# STM32L053C6T6 register map
File version: 1.0
Registers are 32-bit, access not given, reset 0x0 unless marked. A register's access mark holds for its fields unless they carry their own. Offsets are from the block's base; [hi:lo] are bit positions; {n}, {i} and the like mark numbered series.

## LPUART1
Base 0x40004800
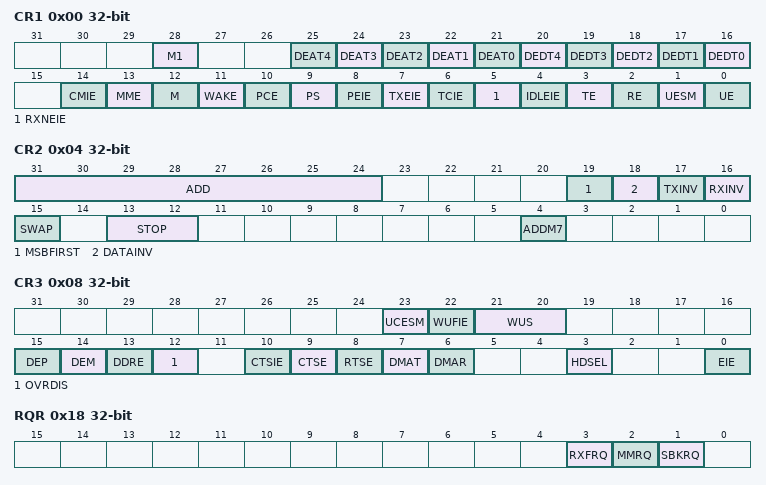
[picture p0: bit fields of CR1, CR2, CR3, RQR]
0x00 CR1
  [28] M1, [n+21] DEAT{n} (n=0..4), [n+16] DEDT{n} (n=0..4), [14] CMIE, [13] MME, [12] M, [11] WAKE, [10] PCE, [9] PS, [8] PEIE, [7] TXEIE, [6] TCIE, [5] RXNEIE, [4] IDLEIE, [3] TE, [2] RE, [1] UESM, [0] UE
0x04 CR2
  [31:24] ADD, [19] MSBFIRST, [18] DATAINV, [17] TXINV, [16] RXINV, [15] SWAP, [13:12] STOP, [4] ADDM7
0x08 CR3
  [23] UCESM, [22] WUFIE, [21:20] WUS, [15] DEP, [14] DEM, [13] DDRE, [12] OVRDIS, [10] CTSIE, [9] CTSE, [8] RTSE, [7] DMAT, [6] DMAR, [3] HDSEL, [0] EIE
0x0C BRR
  [19:0] BRR
0x18 RQR
  [3] RXFRQ, [2] MMRQ, [1] SBKRQ
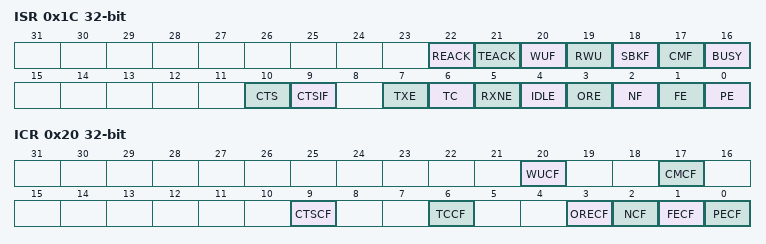
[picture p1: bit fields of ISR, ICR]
0x1C ISR
  [22] REACK, [21] TEACK, [20] WUF, [19] RWU, [18] SBKF, [17] CMF, [16] BUSY, [10] CTS, [9] CTSIF, [7] TXE, [6] TC, [5] RXNE, [4] IDLE, [3] ORE, [2] NF, [1] FE, [0] PE
0x20 ICR
  [20] WUCF, [17] CMCF, [9] CTSCF, [6] TCCF, [3] ORECF, [2] NCF, [1] FECF, [0] PECF
0x24 RDR
  [8:0] RDR
0x28 TDR
  [8:0] TDR

## I2C1
Base 0x40005400
Same registers: I2C2 0x40005800, I2C3 0x40007800
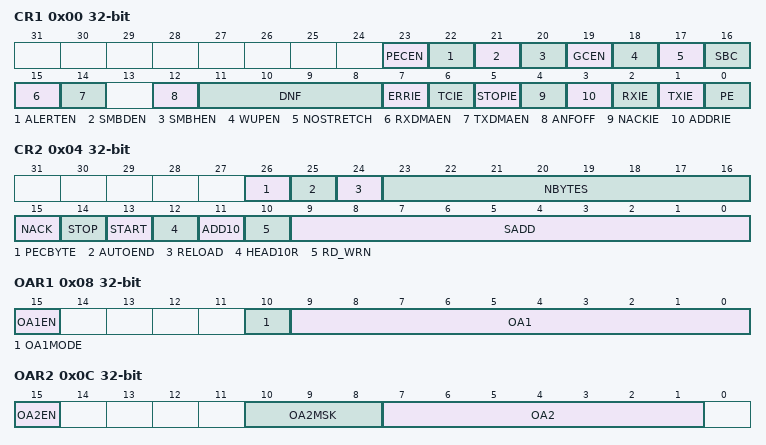
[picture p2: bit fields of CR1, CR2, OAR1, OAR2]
0x00 CR1
  [23] PECEN, [22] ALERTEN, [21] SMBDEN, [20] SMBHEN, [19] GCEN, [18] WUPEN, [17] NOSTRETCH, [16] SBC, [15] RXDMAEN, [14] TXDMAEN, [12] ANFOFF, [11:8] DNF, [7] ERRIE, [6] TCIE, [5] STOPIE, [4] NACKIE, [3] ADDRIE, [2] RXIE, [1] TXIE, [0] PE
0x04 CR2
  [26] PECBYTE, [25] AUTOEND, [24] RELOAD, [23:16] NBYTES, [15] NACK, [14] STOP, [13] START, [12] HEAD10R, [11] ADD10, [10] RD_WRN, [9:0] SADD
0x08 OAR1
  [15] OA1EN, [10] OA1MODE, [9:0] OA1
0x0C OAR2
  [15] OA2EN, [10:8] OA2MSK, [7:1] OA2
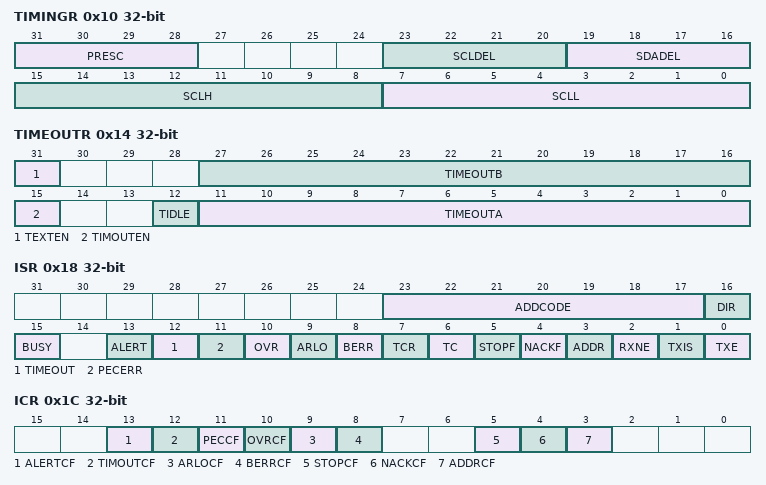
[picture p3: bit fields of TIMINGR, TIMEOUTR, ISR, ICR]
0x10 TIMINGR
  [31:28] PRESC, [23:20] SCLDEL, [19:16] SDADEL, [15:8] SCLH, [7:0] SCLL
0x14 TIMEOUTR
  [31] TEXTEN, [27:16] TIMEOUTB, [15] TIMOUTEN, [12] TIDLE, [11:0] TIMEOUTA
0x18 ISR
  [23:17] ADDCODE, [16] DIR, [15] BUSY, [13] ALERT, [12] TIMEOUT, [11] PECERR, [10] OVR, [9] ARLO, [8] BERR, [7] TCR, [6] TC, [5] STOPF, [4] NACKF, [3] ADDR, [2] RXNE, [1] TXIS, [0] TXE
0x1C ICR
  [13] ALERTCF, [12] TIMOUTCF, [11] PECCF, [10] OVRCF, [9] ARLOCF, [8] BERRCF, [5] STOPCF, [4] NACKCF, [3] ADDRCF
0x20 PECR
  [7:0] PEC
0x24 RXDR
  [7:0] RXDATA
0x28 TXDR
  [7:0] TXDATA

## USBFS
Base 0x40005C00
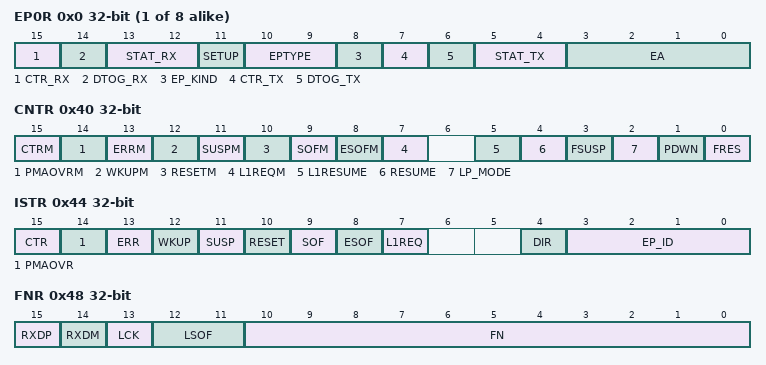
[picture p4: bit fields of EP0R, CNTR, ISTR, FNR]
{0x0+4i} EP{i}R (i=0..7)
  [15] CTR_RX, [14] DTOG_RX, [13:12] STAT_RX, [11] SETUP, [10:9] EPTYPE, [8] EP_KIND, [7] CTR_TX, [6] DTOG_TX, [5:4] STAT_TX, [3:0] EA
0x40 CNTR
  [15] CTRM, [14] PMAOVRM, [13] ERRM, [12] WKUPM, [11] SUSPM, [10] RESETM, [9] SOFM, [8] ESOFM, [7] L1REQM, [5] L1RESUME, [4] RESUME, [3] FSUSP, [2] LP_MODE, [1] PDWN, [0] FRES
0x44 ISTR
  [15] CTR, [14] PMAOVR, [13] ERR, [12] WKUP, [11] SUSP, [10] RESET, [9] SOF, [8] ESOF, [7] L1REQ, [4] DIR, [3:0] EP_ID
0x48 FNR
  [15] RXDP, [14] RXDM, [13] LCK, [12:11] LSOF, [10:0] FN
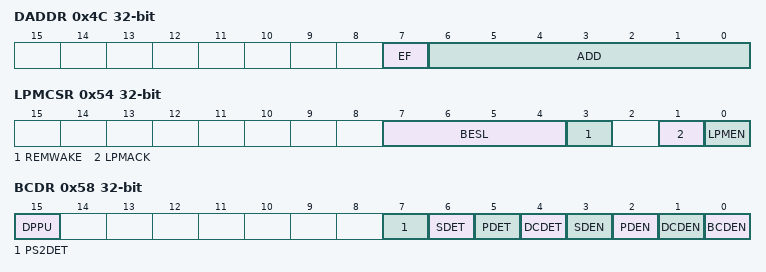
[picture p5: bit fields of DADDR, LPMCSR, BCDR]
0x4C DADDR
  [7] EF, [6:0] ADD
0x50 BTABLE
  [15:3] BTABLE
0x54 LPMCSR
  [7:4] BESL, [3] REMWAKE, [1] LPMACK, [0] LPMEN
0x58 BCDR
  [15] DPPU, [7] PS2DET, [6] SDET, [5] PDET, [4] DCDET, [3] SDEN, [2] PDEN, [1] DCDEN, [0] BCDEN

## CRS
Base 0x40006C00
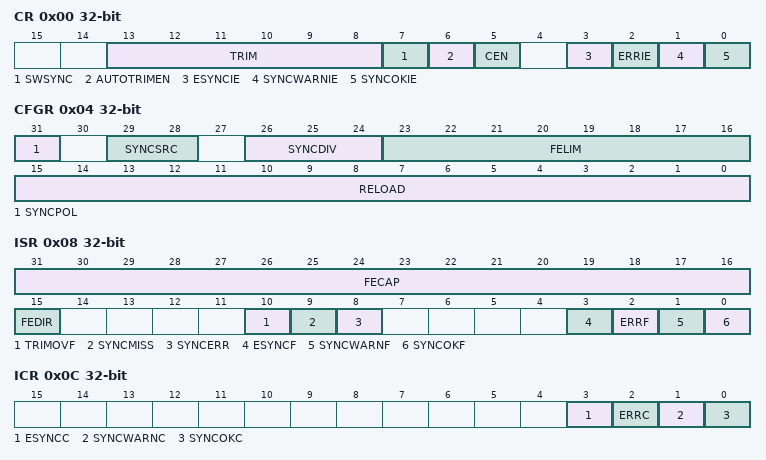
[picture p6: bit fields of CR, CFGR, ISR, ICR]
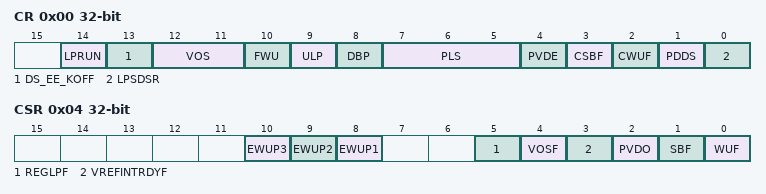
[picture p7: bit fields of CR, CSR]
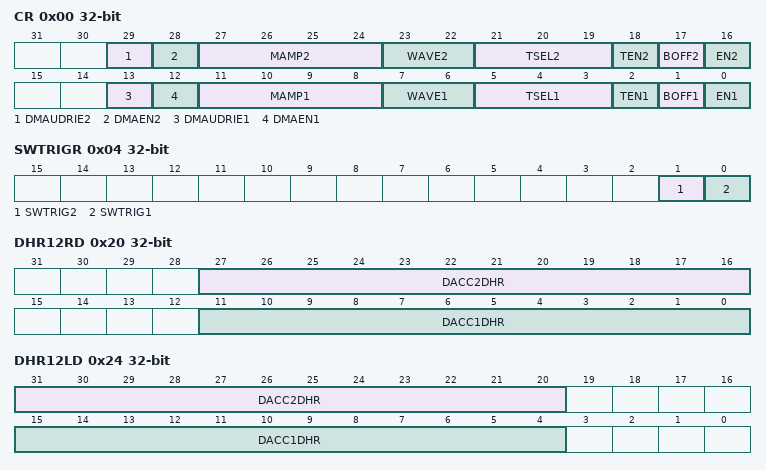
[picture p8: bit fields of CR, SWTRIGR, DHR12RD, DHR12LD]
0x00 CR
  [13:8] TRIM, [7] SWSYNC, [6] AUTOTRIMEN, [5] CEN, [3] ESYNCIE, [2] ERRIE, [1] SYNCWARNIE, [0] SYNCOKIE
0x04 CFGR
  [31] SYNCPOL, [29:28] SYNCSRC, [26:24] SYNCDIV, [23:16] FELIM, [15:0] RELOAD
0x08 ISR
  [31:16] FECAP, [15] FEDIR, [10] TRIMOVF, [9] SYNCMISS, [8] SYNCERR, [3] ESYNCF, [2] ERRF, [1] SYNCWARNF, [0] SYNCOKF
0x0C ICR
  [3] ESYNCC, [2] ERRC, [1] SYNCWARNC, [0] SYNCOKC

## PWR
Base 0x40007000
0x00 CR
  [14] LPRUN, [13] DS_EE_KOFF, [12:11] VOS, [10] FWU, [9] ULP, [8] DBP, [7:5] PLS, [4] PVDE, [3] CSBF, [2] CWUF, [1] PDDS, [0] LPSDSR
0x04 CSR
  [10] EWUP3, [9] EWUP2, [8] EWUP1, [5] REGLPF, [4] VOSF, [3] VREFINTRDYF, [2] PVDO, [1] SBF, [0] WUF

## DAC12
Base 0x40007400
0x00 CR
  [29] DMAUDRIE2, [28] DMAEN2, [27:24] MAMP2, [23:22] WAVE2, [21:19] TSEL2, [18] TEN2, [17] BOFF2, [16] EN2, [13] DMAUDRIE1, [12] DMAEN1, [11:8] MAMP1, [7:6] WAVE1, [5:3] TSEL1, [2] TEN1, [1] BOFF1, [0] EN1
0x04 SWTRIGR
  [1] SWTRIG2, [0] SWTRIG1
0x08 DHR12R1
  [11:0] DACC1DHR
0x0C DHR12L1
  [15:4] DACC1DHR
0x10 DHR8R1
  [7:0] DACC1DHR
0x14 DHR12R2
  [11:0] DACC2DHR
0x18 DHR12L2
  [15:4] DACC2DHR
0x1C DHR8R2
  [7:0] DACC2DHR
0x20 DHR12RD
  [27:16] DACC2DHR, [11:0] DACC1DHR
0x24 DHR12LD
  [31:20] DACC2DHR, [15:4] DACC1DHR
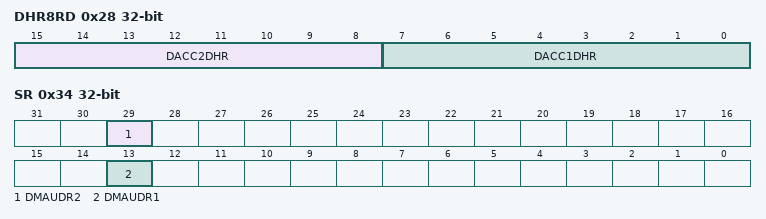
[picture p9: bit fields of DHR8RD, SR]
0x28 DHR8RD
  [15:8] DACC2DHR, [7:0] DACC1DHR
0x2C DOR1
  [11:0] DACC1DOR
0x30 DOR2
  [11:0] DACC2DOR
0x34 SR
  [29] DMAUDR2, [13] DMAUDR1
